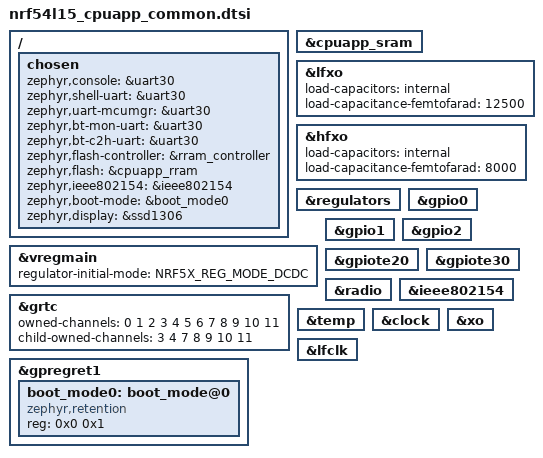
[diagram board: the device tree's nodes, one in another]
/*
 * Copyright (c) 2024 Nordic Semiconductor ASA
 *
 * SPDX-License-Identifier: Apache-2.0
 */

/* This file is common to the secure and non-secure domain */

#include "idea_mesh_tracker_c2_common.dtsi"

/ {
	chosen {
		zephyr,console = &uart30;
		zephyr,shell-uart = &uart30;
		zephyr,uart-mcumgr = &uart30;
		zephyr,bt-mon-uart = &uart30;
		zephyr,bt-c2h-uart = &uart30;
		zephyr,flash-controller = &rram_controller;
		zephyr,flash = &cpuapp_rram;
		zephyr,ieee802154 = &ieee802154;
		zephyr,boot-mode = &boot_mode0;
		zephyr,display = &ssd1306;
	};
};

&cpuapp_sram {
	status = "okay";
};

&lfxo {
	status = "okay";
	load-capacitors = "internal";
	load-capacitance-femtofarad = <12500>;
};

&hfxo {
	status = "okay";
	load-capacitors = "internal";
	load-capacitance-femtofarad = <8000>;
};

&regulators {
	status = "okay";
};

&vregmain {
	status = "okay";
	regulator-initial-mode = <NRF5X_REG_MODE_DCDC>;
};

&grtc {
	owned-channels = <0 1 2 3 4 5 6 7 8 9 10 11>;
	/* Channels 7-11 reserved for Zero Latency IRQs, 3-4 for FLPR */
	child-owned-channels = <3 4 7 8 9 10 11>;
	status = "okay";
};

&gpio0 {
	status = "okay";
};

&gpio1 {
	status = "okay";
};

&gpio2 {
	status = "okay";
};

&gpiote20 {
	status = "okay";
};

&gpiote30 {
	status = "okay";
};

&radio {
	status = "okay";
};

&ieee802154 {
	status = "okay";
};

&temp {
	status = "okay";
};

&clock {
	status = "okay";
};

&xo {
	status = "okay";
};

&lfclk {
	status = "okay";
};

&gpregret1 {
	status = "okay";

	boot_mode0: boot_mode@0 {
		compatible = "zephyr,retention";
		status = "okay";
		reg = <0x0 0x1>;
	};
};

#include "idea_mesh_tracker_c2_peripherals.dtsi"
